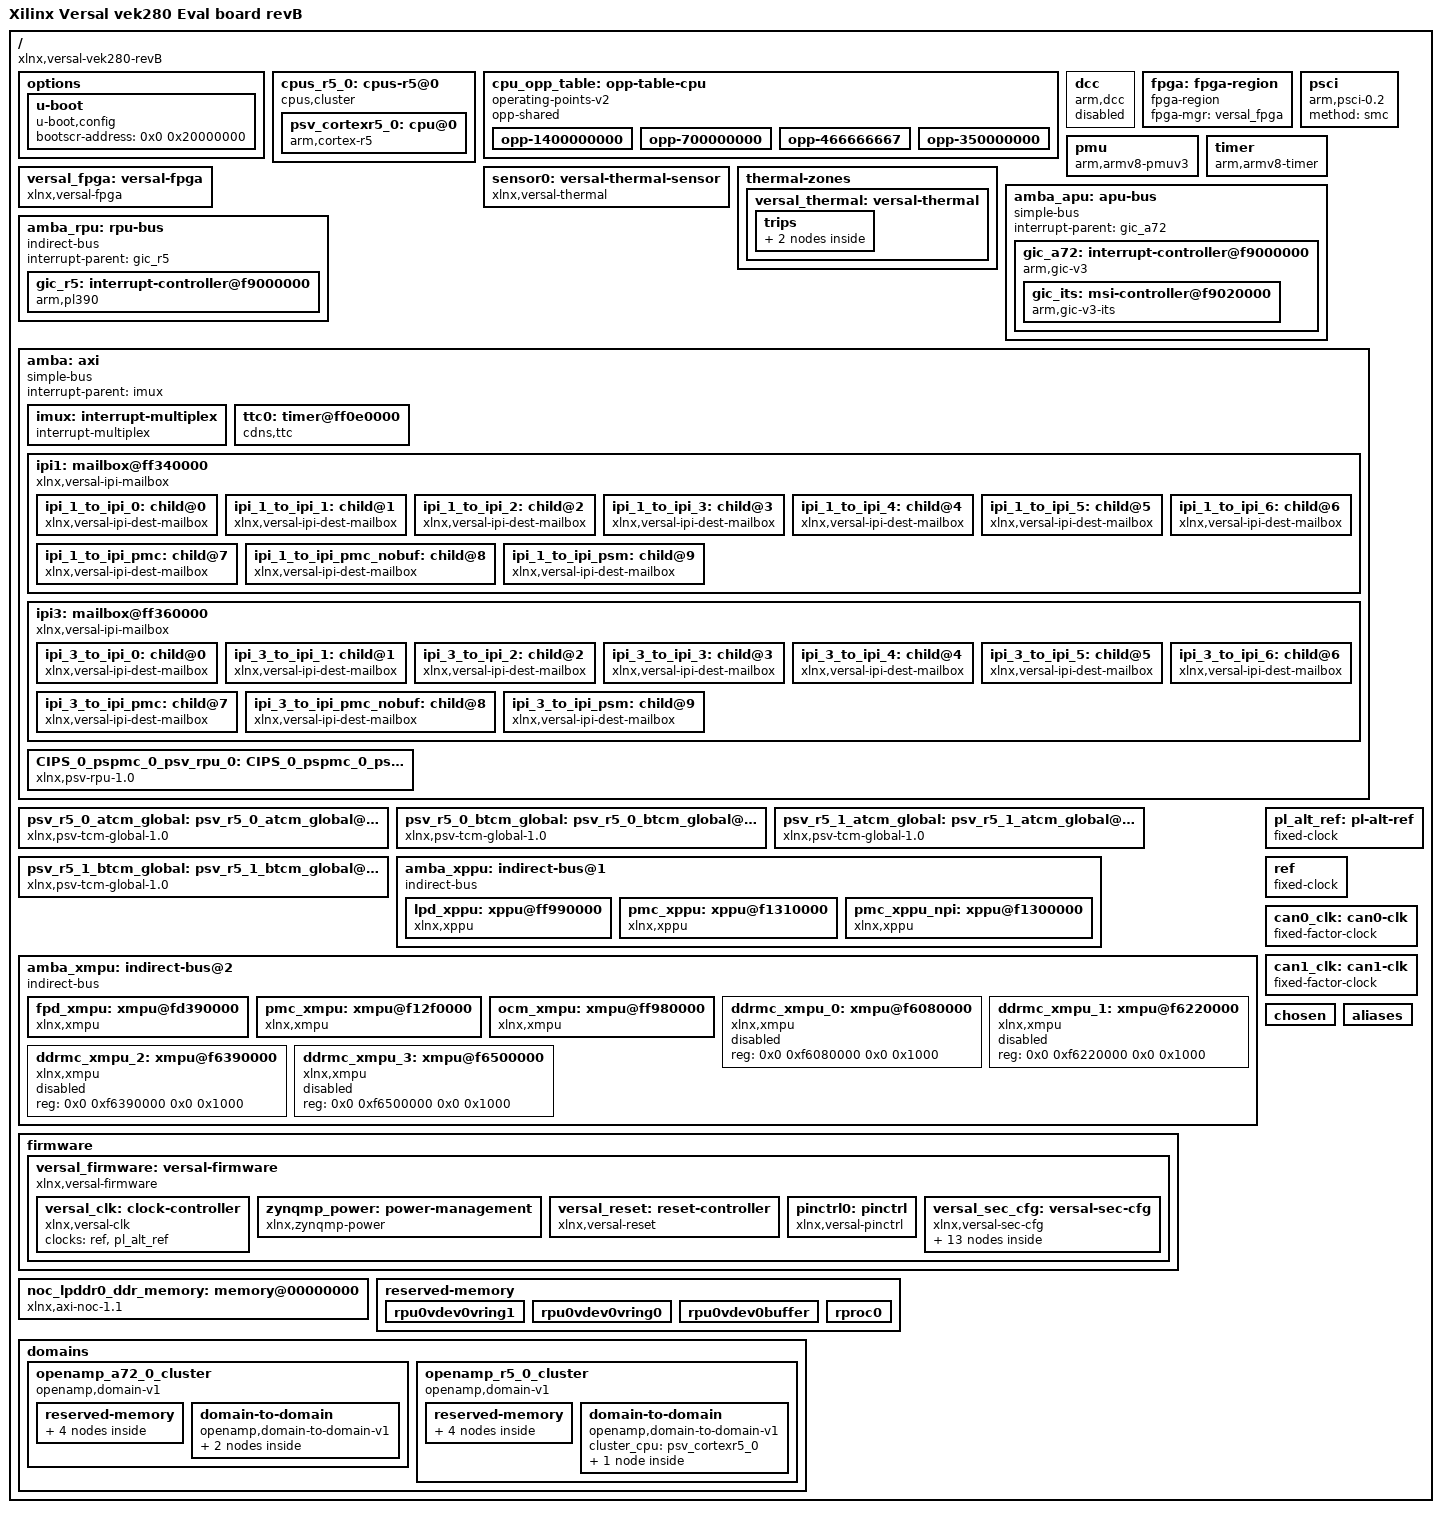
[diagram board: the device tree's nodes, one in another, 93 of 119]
/dts-v1/;
/ {
        compatible = "xlnx,versal-vek280-revB", "xlnx,versal-vek280", "xlnx,versal", "Xilinx Versal vek280 Eval board revB", "Xilinx Versal vek280 Eval board revB";
        #address-cells = <0x2>;
        #size-cells = <0x2>;
        model = "Xilinx Versal vek280 Eval board revB";
        board = "vek280";
        device_id = "xcve2802";
        slrcount = <0x1>;
        family = "Versal";
        speed_grade = "2MP";

        options {

                u-boot {
                        compatible = "u-boot,config";
                        bootscr-address = <0x0 0x20000000>;
                };
        };

        cpus_r5_0: cpus-r5@0 {
                phandle = <0xab>;
                #address-cells = <0x1>;
                #size-cells = <0x0>;
                compatible = "cpus,cluster";
                address-map = <0xf0000000 &amba 0xf0000000 0x10000000>,
                 <0xf9000000 &amba_rpu 0xf9000000 0x3000>,
                 <0x40000 &noc_lpddr0_ddr_memory 0x40000 0x7ffc0000>,
                 <0xff340000 &ipi1 0xff340000 0x10000>,
                 <0xf12f0000 &pmc_xmpu 0xf12f0000 0x10000>,
                 <0xf1300000 &pmc_xppu_npi 0xf1300000 0x10000>,
                 <0xf1310000 &pmc_xppu 0xf1310000 0x10000>,
                 <0xfd390000 &fpd_xmpu 0xfd390000 0x10000>,
                 <0xff0e0000 &ttc0 0xff0e0000 0x10000>,
                 <0xff980000 &ocm_xmpu 0xff980000 0x10000>,
                 <0xff990000 &lpd_xppu 0xff990000 0x10000>,
                 <0xff9a0000 &CIPS_0_pspmc_0_psv_rpu_0 0xff9a0000 0x10000>,
                 <0xf9000000 &gic_r5 0xf9000000 0x3000>;
                #ranges-address-cells = <0x1>;
                #ranges-size-cells = <0x1>;

                psv_cortexr5_0: cpu@0 {
                        phandle = <0xac>;
                        compatible = "arm,cortex-r5";
                        device_type = "cpu";
                        reg = <0x0>;
                        operating-points-v2 = <&cpu_opp_table>;
                        power-domains = <&versal_firmware 0x18110005>;
                        xlnx,is-cache-coherent = <0x0>;
                        xlnx,pss-ref-clk-freq = <0x1fca034>;
                        xlnx,ip-name = "psv_cortexr5";
                        access-val = <0xff>;
                        bus-handle = <0x1>;
                        xlnx,cpu-clk-freq-hz = <0x23c343db>;
                        cpu-frequency = <0x23c343db>;
                };
        };

        cpu_opp_table: opp-table-cpu {
                phandle = <0x7d>;
                compatible = "operating-points-v2";
                opp-shared;

                opp-1400000000 {
                        opp-hz = <0x0 0x53724e00>;
                        clock-latency-ns = <0x7a120>;
                        opp-microvolt = <0xf4240>;
                };

                opp-700000000 {
                        opp-hz = <0x0 0x29b92700>;
                        clock-latency-ns = <0x7a120>;
                        opp-microvolt = <0xf4240>;
                };

                opp-466666667 {
                        opp-hz = <0x0 0x1bd0c4ab>;
                        clock-latency-ns = <0x7a120>;
                        opp-microvolt = <0xf4240>;
                };

                opp-350000000 {
                        opp-hz = <0x0 0x14dc9380>;
                        clock-latency-ns = <0x7a120>;
                        opp-microvolt = <0xf4240>;
                };
        };

        dcc: dcc {
                phandle = <0xaf>;
                compatible = "arm,dcc";
                status = "disabled";
                bootph-all;
        };

        fpga: fpga-region {
                phandle = <0xb0>;
                compatible = "fpga-region";
                fpga-mgr = <&versal_fpga>;
                #address-cells = <0x2>;
                #size-cells = <0x2>;
        };

        psci: psci {
                phandle = <0xb1>;
                compatible = "arm,psci-0.2";
                method = "smc";
        };

        pmu {
                compatible = "arm,armv8-pmuv3";
                interrupt-parent = <&imux>;
                interrupts = <0x1 0x7 0x304>;
        };

        timer: timer {
                phandle = <0xb2>;
                compatible = "arm,armv8-timer";
                interrupt-parent = <&imux>;
                interrupts = <0x1 0xd 0x4 0x1 0xe 0x4 0x1 0xb 0x4 0x1 0xa 0x4>;
        };

        versal_fpga: versal-fpga {
                phandle = <0x97>;
                compatible = "xlnx,versal-fpga";
        };

        sensor0: versal-thermal-sensor {
                phandle = <0x99>;
                compatible = "xlnx,versal-thermal";
                #thermal-sensor-cells = <0x0>;
                io-channel-names = "sysmon-temp-channel";
        };

        thermal-zones {

                versal_thermal: versal-thermal {
                        phandle = <0xb3>;
                        polling-delay-passive = <0xfa>;
                        polling-delay = <0x3e8>;
                        thermal-sensors = <0x99>;

                        trips {

                                temp_alert: temp-alert {
                                        phandle = <0xb4>;
                                        temperature = <0x11170>;
                                        hysteresis = <0x0>;
                                        type = "passive";
                                };

                                ot_crit: ot-crit {
                                        phandle = <0xb5>;
                                        temperature = <0x1e848>;
                                        hysteresis = <0x0>;
                                        type = "critical";
                                };
                        };
                };
        };

        amba_apu: apu-bus {
                phandle = <0x2>;
                compatible = "simple-bus";
                #address-cells = <0x2>;
                #size-cells = <0x2>;
                ranges;
                interrupt-parent = <&gic_a72>;
                bootph-all;

                gic_a72: interrupt-controller@f9000000 {
                        phandle = <0x4d>;
                        compatible = "arm,gic-v3";
                        #interrupt-cells = <0x3>;
                        #address-cells = <0x2>;
                        #size-cells = <0x2>;
                        ranges;
                        reg = <0x0 0xf9000000 0x0 0x80000 0x0 0xf9080000 0x0 0x80000>;
                        interrupt-controller;
                        interrupt-parent = <&gic_a72>;
                        interrupts = <0x1 0x9 0x4>;
                        status = "okay";
                        xlnx,apu-gic-its-ctl = <0xf9020000>;
                        xlnx,ip-name = "psv_acpu_gic";
                        xlnx,name = "CIPS_0_pspmc_0_psv_acpu_gic";

                        gic_its: msi-controller@f9020000 {
                                phandle = <0x8>;
                                compatible = "arm,gic-v3-its";
                                status = "okay";
                                msi-controller;
                                #msi-cells = <0x1>;
                                reg = <0x0 0xf9020000 0x0 0x20000>;
                        };
                };
        };

        amba_rpu: rpu-bus {
                phandle = <0x8a>;
                compatible = "indirect-bus";
                #address-cells = <0x2>;
                #size-cells = <0x2>;
                ranges;
                interrupt-parent = <&gic_r5>;
                bootph-all;

                gic_r5: interrupt-controller@f9000000 {
                        phandle = <0x8f>;
                        compatible = "arm,pl390";
                        #interrupt-cells = <0x3>;
                        interrupt-controller;
                        status = "okay";
                        reg = <0x0 0xf9000000 0x0 0x1000 0x0 0xf9001000 0x0 0x1000>;
                        xlnx,ip-name = "psv_rcpu_gic";
                        xlnx,name = "CIPS_0_pspmc_0_psv_rcpu_gic";
                };
        };

        amba: axi {
                phandle = <0x1>;
                compatible = "simple-bus";
                #address-cells = <0x2>;
                #size-cells = <0x2>;
                ranges;
                interrupt-parent = <&imux>;
                bootph-all;

                imux: interrupt-multiplex {
                        phandle = <0x98>;
                        compatible = "interrupt-multiplex";
                        #address-cells = <0x0>;
                        #interrupt-cells = <0x3>;
                        interrupt-controller;
                        interrupt-parent = <&gic_a72>,
                         <&gic_r5>;
                        interrupt-map-mask = <0x0 0xffff 0x0>;
                        interrupt-map = <0x0 0x14 0x0 &gic_a72 0x0 0x14 0x1>,
                         <0x0 0x15 0x0 &gic_a72 0x0 0x15 0x1>,
                         <0x0 0x6a 0x0 &gic_a72 0x0 0x6a 0x4>,
                         <0x0 0x3c 0x0 &gic_a72 0x0 0x3c 0x4>,
                         <0x0 0x3d 0x0 &gic_a72 0x0 0x3d 0x4>,
                         <0x0 0x3e 0x0 &gic_a72 0x0 0x3e 0x4>,
                         <0x0 0x3f 0x0 &gic_a72 0x0 0x3f 0x4>,
                         <0x0 0x40 0x0 &gic_a72 0x0 0x40 0x4>,
                         <0x0 0x41 0x0 &gic_a72 0x0 0x41 0x4>,
                         <0x0 0x42 0x0 &gic_a72 0x0 0x42 0x4>,
                         <0x0 0x43 0x0 &gic_a72 0x0 0x43 0x4>,
                         <0x0 0x38 0x0 &gic_a72 0x0 0x38 0x4>,
                         <0x0 0x3a 0x0 &gic_a72 0x0 0x3a 0x4>,
                         <0x0 0xd 0x0 &gic_a72 0x0 0xd 0x4>,
                         <0x0 0x7a 0x0 &gic_a72 0x0 0x7a 0x4>,
                         <0x0 0xe 0x0 &gic_a72 0x0 0xe 0x4>,
                         <0x0 0xf 0x0 &gic_a72 0x0 0xf 0x4>,
                         <0x0 0x8e 0x0 &gic_a72 0x0 0x8e 0x4>,
                         <0x0 0x8f 0x0 &gic_a72 0x0 0x8f 0x4>,
                         <0x0 0x7e 0x0 &gic_a72 0x0 0x7e 0x4>,
                         <0x0 0x80 0x0 &gic_a72 0x0 0x80 0x4>,
                         <0x0 0x12 0x0 &gic_a72 0x0 0x12 0x4>,
                         <0x0 0x13 0x0 &gic_a72 0x0 0x13 0x4>,
                         <0x0 0x6b 0x0 &gic_a72 0x0 0x6b 0x4>,
                         <0x0 0x7c 0x0 &gic_a72 0x0 0x7c 0x4>,
                         <0x0 0x7d 0x0 &gic_a72 0x0 0x7d 0x4>,
                         <0x0 0x10 0x0 &gic_a72 0x0 0x10 0x4>,
                         <0x0 0x11 0x0 &gic_a72 0x0 0x11 0x4>,
                         <0x0 0x16 0x0 &gic_a72 0x0 0x16 0x4>,
                         <0x0 0x1a 0x0 &gic_a72 0x0 0x1a 0x4>,
                         <0x0 0x4a 0x0 &gic_a72 0x0 0x4a 0x4>,
                         <0x0 0x48 0x0 &gic_a72 0x0 0x48 0x4>,
                         <0x0 0x1e 0x0 &gic_a72 0x0 0x1e 0x4>,
                         <0x0 0x1f 0x0 &gic_a72 0x0 0x1f 0x4>,
                         <0x0 0x83 0x0 &gic_a72 0x0 0x83 0x4>,
                         <0x0 0x84 0x0 &gic_a72 0x0 0x84 0x4>,
                         <0x0 0x14 0x0 &gic_r5 0x0 0x14 0x1>,
                         <0x0 0x15 0x0 &gic_r5 0x0 0x15 0x1>,
                         <0x0 0x6a 0x0 &gic_r5 0x0 0x6a 0x4>,
                         <0x0 0x3c 0x0 &gic_r5 0x0 0x3c 0x4>,
                         <0x0 0x3d 0x0 &gic_r5 0x0 0x3d 0x4>,
                         <0x0 0x3e 0x0 &gic_r5 0x0 0x3e 0x4>,
                         <0x0 0x3f 0x0 &gic_r5 0x0 0x3f 0x4>,
                         <0x0 0x40 0x0 &gic_r5 0x0 0x40 0x4>,
                         <0x0 0x41 0x0 &gic_r5 0x0 0x41 0x4>,
                         <0x0 0x42 0x0 &gic_r5 0x0 0x42 0x4>,
                         <0x0 0x43 0x0 &gic_r5 0x0 0x43 0x4>,
                         <0x0 0x38 0x0 &gic_r5 0x0 0x38 0x4>,
                         <0x0 0x3a 0x0 &gic_r5 0x0 0x3a 0x4>,
                         <0x0 0xd 0x0 &gic_r5 0x0 0xd 0x4>,
                         <0x0 0x7a 0x0 &gic_r5 0x0 0x7a 0x4>,
                         <0x0 0xe 0x0 &gic_r5 0x0 0xe 0x4>,
                         <0x0 0xf 0x0 &gic_r5 0x0 0xf 0x4>,
                         <0x0 0x8e 0x0 &gic_r5 0x0 0x8e 0x4>,
                         <0x0 0x8f 0x0 &gic_r5 0x0 0x8f 0x4>,
                         <0x0 0x7e 0x0 &gic_r5 0x0 0x7e 0x4>,
                         <0x0 0x80 0x0 &gic_r5 0x0 0x80 0x4>,
                         <0x0 0x12 0x0 &gic_r5 0x0 0x12 0x4>,
                         <0x0 0x13 0x0 &gic_r5 0x0 0x13 0x4>,
                         <0x0 0x6b 0x0 &gic_r5 0x0 0x6b 0x4>,
                         <0x0 0x7c 0x0 &gic_r5 0x0 0x7c 0x4>,
                         <0x0 0x7d 0x0 &gic_r5 0x0 0x7d 0x4>,
                         <0x0 0x10 0x0 &gic_r5 0x0 0x10 0x4>,
                         <0x0 0x11 0x0 &gic_r5 0x0 0x11 0x4>,
                         <0x0 0x16 0x0 &gic_r5 0x0 0x16 0x4>,
                         <0x0 0x1a 0x0 &gic_r5 0x0 0x1a 0x4>,
                         <0x0 0x4a 0x0 &gic_r5 0x0 0x4a 0x4>,
                         <0x0 0x48 0x0 &gic_r5 0x0 0x48 0x4>,
                         <0x0 0x1e 0x0 &gic_r5 0x0 0x1e 0x4>,
                         <0x0 0x1f 0x0 &gic_r5 0x0 0x1f 0x4>,
                         <0x0 0x83 0x0 &gic_r5 0x0 0x83 0x4>,
                         <0x0 0x84 0x0 &gic_r5 0x0 0x84 0x4>;
                };

                ttc0: timer@ff0e0000 {
                        phandle = <0x64>;
                        compatible = "cdns,ttc";
                        status = "okay";
                        interrupts = <0x0 0x25 0x4 0x0 0x26 0x4 0x0 0x27 0x4>;
                        interrupt-parent = <&imux>;
                        reg = <0x0 0xff0e0000 0x0 0x1000>;
                        timer-width = <0x20>;
                        clocks = <&versal_clk 0x27>;
                        power-domains = <&versal_firmware 0x18224024>;
                        xlnx,ttc-board-interface = "custom";
                        xlnx,ttc-clk2-freq-hz = <0x8f0d0f7>;
                        xlnx,ttc-clk1-clksrc = <0x0>;
                        xlnx,clock-freq = <0x8f0d0f7>;
                        xlnx,ttc-clk2-clksrc = <0x0>;
                        xlnx,ip-name = "psv_ttc";
                        xlnx,ttc-clk0-freq-hz = <0x8f0d0f7>;
                        xlnx,ttc-clk1-freq-hz = <0x8f0d0f7>;
                        xlnx,ttc-clk0-clksrc = <0x0>;
                        xlnx,name = "CIPS_0_pspmc_0_psv_ttc_0";
                };

                ipi1: mailbox@ff340000 {
                        status = "okay";
                        compatible = "xlnx,versal-ipi-mailbox";
                        interrupt-parent = <&imux>;
                        interrupts = <0x0 0x1f 0x4>;
                        reg = <0x0 0xff340000 0x0 0x10000 0x0 0xff3f0600 0x0 0x200>;
                        xlnx,ipi-bitmask = <0x8>;
                        xlnx,ipi-id = <0x3>;
                        xlnx,ipi-buf-index = <0x3>;
                        #address-cells = <0x2>;
                        #size-cells = <0x2>;
                        ranges;
                        xlnx,cpu-name = "R5_0";
                        xlnx,buffer-base = <0xff3f0600>;
                        xlnx,buffer-index = <0x3>;
                        xlnx,ip-name = "psv_ipi";
                        xlnx,ipi-target-count = <0xa>;
                        reg-names = "ctrl", "msg";
                        xlnx,int-id = <0x3f>;
                        xlnx,bit-position = <0x3>;
                        xlnx,name = "CIPS_0_pspmc_0_psv_ipi_1";
                        phandle = <0x8b>;

                        ipi_1_to_ipi_0: child@0 {
                                phandle = <0xfa>;
                                compatible = "xlnx,versal-ipi-dest-mailbox";
                                xlnx,ipi-bitmask = <0x4>;
                                xlnx,cpu-name = "A72";
                                xlnx,ipi-rsp-msg-buf = <0xff3f06a0>;
                                #mbox-cells = <0x1>;
                                xlnx,ipi-id = <0x2>;
                                reg = <0x0 0xff330000 0x0 0x10000 0x0 0xff3f0400 0x0 0x200>;
                                xlnx,ipi-buf-index = <0x2>;
                                xlnx,ipi-req-msg-buf = <0xff3f0680>;
                                reg-names = "ctrl", "msg";
                        };

                        ipi_1_to_ipi_1: child@1 {
                                phandle = <0xfb>;
                                compatible = "xlnx,versal-ipi-dest-mailbox";
                                xlnx,ipi-bitmask = <0x8>;
                                xlnx,cpu-name = "R5_0";
                                xlnx,ipi-rsp-msg-buf = <0xff3f06e0>;
                                #mbox-cells = <0x1>;
                                xlnx,ipi-id = <0x3>;
                                reg = <0x0 0xff340000 0x0 0x10000 0x0 0xff3f0600 0x0 0x200>;
                                xlnx,ipi-buf-index = <0x3>;
                                xlnx,ipi-req-msg-buf = <0xff3f06c0>;
                                reg-names = "ctrl", "msg";
                        };

                        ipi_1_to_ipi_2: child@2 {
                                phandle = <0xfc>;
                                compatible = "xlnx,versal-ipi-dest-mailbox";
                                xlnx,ipi-bitmask = <0x10>;
                                xlnx,cpu-name = "R5_1";
                                xlnx,ipi-rsp-msg-buf = <0xff3f0720>;
                                #mbox-cells = <0x1>;
                                xlnx,ipi-id = <0x4>;
                                reg = <0x0 0xff350000 0x0 0x10000 0x0 0xff3f0800 0x0 0x200>;
                                xlnx,ipi-buf-index = <0x4>;
                                xlnx,ipi-req-msg-buf = <0xff3f0700>;
                                reg-names = "ctrl", "msg";
                        };

                        ipi_1_to_ipi_3: child@3 {
                                phandle = <0xfd>;
                                compatible = "xlnx,versal-ipi-dest-mailbox";
                                xlnx,ipi-bitmask = <0x20>;
                                xlnx,cpu-name = "A72";
                                xlnx,ipi-rsp-msg-buf = <0xff3f0760>;
                                #mbox-cells = <0x1>;
                                xlnx,ipi-id = <0x5>;
                                reg = <0x0 0xff360000 0x0 0x10000 0x0 0xff3f0a00 0x0 0x200>;
                                xlnx,ipi-buf-index = <0x5>;
                                xlnx,ipi-req-msg-buf = <0xff3f0740>;
                                reg-names = "ctrl", "msg";
                        };

                        ipi_1_to_ipi_4: child@4 {
                                phandle = <0xfe>;
                                compatible = "xlnx,versal-ipi-dest-mailbox";
                                xlnx,ipi-bitmask = <0x40>;
                                xlnx,cpu-name = "A72";
                                xlnx,ipi-rsp-msg-buf = <0xff3f07a0>;
                                #mbox-cells = <0x1>;
                                xlnx,ipi-id = <0x6>;
                                reg = <0x0 0xff370000 0x0 0x10000 0x0 0xff3f0c00 0x0 0x200>;
                                xlnx,ipi-buf-index = <0x6>;
                                xlnx,ipi-req-msg-buf = <0xff3f0780>;
                                reg-names = "ctrl", "msg";
                        };

                        ipi_1_to_ipi_5: child@5 {
                                phandle = <0xff>;
                                compatible = "xlnx,versal-ipi-dest-mailbox";
                                xlnx,ipi-bitmask = <0x80>;
                                xlnx,cpu-name = "A72";
                                xlnx,ipi-rsp-msg-buf = <0xff3f07e0>;
                                #mbox-cells = <0x1>;
                                xlnx,ipi-id = <0x7>;
                                reg = <0x0 0xff380000 0x0 0x10000 0x0 0xff3f0e00 0x0 0x200>;
                                xlnx,ipi-buf-index = <0x7>;
                                xlnx,ipi-req-msg-buf = <0xff3f07c0>;
                                reg-names = "ctrl", "msg";
                        };

                        ipi_1_to_ipi_6: child@6 {
                                phandle = <0x100>;
                                compatible = "xlnx,versal-ipi-dest-mailbox";
                                xlnx,ipi-bitmask = <0x200>;
                                xlnx,cpu-name = "A72";
                                #mbox-cells = <0x1>;
                                xlnx,ipi-id = <0x9>;
                                reg = <0x0 0xff3a0000 0x0 0x10000>;
                                xlnx,ipi-buf-index = <0xffff>;
                                reg-names = "ctrl";
                        };

                        ipi_1_to_ipi_pmc: child@7 {
                                phandle = <0x101>;
                                compatible = "xlnx,versal-ipi-dest-mailbox";
                                xlnx,ipi-bitmask = <0x2>;
                                xlnx,cpu-name = "PMC";
                                xlnx,ipi-rsp-msg-buf = <0xff3f0660>;
                                #mbox-cells = <0x1>;
                                xlnx,ipi-id = <0x1>;
                                reg = <0x0 0xff320000 0x0 0x10000 0x0 0xff3f0200 0x0 0x200>;
                                xlnx,ipi-buf-index = <0x1>;
                                xlnx,ipi-req-msg-buf = <0xff3f0640>;
                                reg-names = "ctrl", "msg";
                        };

                        ipi_1_to_ipi_pmc_nobuf: child@8 {
                                phandle = <0x102>;
                                compatible = "xlnx,versal-ipi-dest-mailbox";
                                xlnx,ipi-bitmask = <0x100>;
                                xlnx,cpu-name = "PMC";
                                #mbox-cells = <0x1>;
                                xlnx,ipi-id = <0x8>;
                                reg = <0x0 0xff390000 0x0 0x10000>;
                                xlnx,ipi-buf-index = <0xffff>;
                                reg-names = "ctrl";
                        };

                        ipi_1_to_ipi_psm: child@9 {
                                phandle = <0x103>;
                                compatible = "xlnx,versal-ipi-dest-mailbox";
                                xlnx,ipi-bitmask = <0x1>;
                                xlnx,cpu-name = "PSM";
                                xlnx,ipi-rsp-msg-buf = <0xff3f0620>;
                                #mbox-cells = <0x1>;
                                xlnx,ipi-id = <0x0>;
                                reg = <0x0 0xff310000 0x0 0x10000 0x0 0xff3f0000 0x0 0x200>;
                                xlnx,ipi-buf-index = <0x0>;
                                xlnx,ipi-req-msg-buf = <0xff3f0600>;
                                reg-names = "ctrl", "msg";
                        };
                };

                ipi3: mailbox@ff360000 {
                        status = "okay";
                        compatible = "xlnx,versal-ipi-mailbox";
                        interrupt-parent = <&imux>;
                        interrupts = <0x0 0x21 0x4>;
                        reg = <0x0 0xff360000 0x0 0x10000 0x0 0xff3f0a00 0x0 0x200>;
                        xlnx,ipi-bitmask = <0x20>;
                        xlnx,ipi-id = <0x5>;
                        xlnx,ipi-buf-index = <0x5>;
                        #address-cells = <0x2>;
                        #size-cells = <0x2>;
                        ranges;
                        xlnx,cpu-name = "A72";
                        xlnx,buffer-base = <0xff3f0a00>;
                        xlnx,buffer-index = <0x5>;
                        xlnx,ip-name = "psv_ipi";
                        xlnx,ipi-target-count = <0xa>;
                        reg-names = "ctrl", "msg";
                        xlnx,int-id = <0x41>;
                        xlnx,bit-position = <0x5>;
                        xlnx,name = "CIPS_0_pspmc_0_psv_ipi_3";
                        phandle = <0xa>;

                        ipi_3_to_ipi_0: child@0 {
                                phandle = <0x10e>;
                                compatible = "xlnx,versal-ipi-dest-mailbox";
                                xlnx,ipi-bitmask = <0x4>;
                                xlnx,cpu-name = "A72";
                                xlnx,ipi-rsp-msg-buf = <0xff3f0aa0>;
                                #mbox-cells = <0x1>;
                                xlnx,ipi-id = <0x2>;
                                reg = <0x0 0xff330000 0x0 0x10000 0x0 0xff3f0400 0x0 0x200>;
                                xlnx,ipi-buf-index = <0x2>;
                                xlnx,ipi-req-msg-buf = <0xff3f0a80>;
                                reg-names = "ctrl", "msg";
                        };

                        ipi_3_to_ipi_1: child@1 {
                                phandle = <0x10f>;
                                compatible = "xlnx,versal-ipi-dest-mailbox";
                                xlnx,ipi-bitmask = <0x8>;
                                xlnx,cpu-name = "R5_0";
                                xlnx,ipi-rsp-msg-buf = <0xff3f0ae0>;
                                #mbox-cells = <0x1>;
                                xlnx,ipi-id = <0x3>;
                                reg = <0x0 0xff340000 0x0 0x10000 0x0 0xff3f0600 0x0 0x200>;
                                xlnx,ipi-buf-index = <0x3>;
                                xlnx,ipi-req-msg-buf = <0xff3f0ac0>;
                                reg-names = "ctrl", "msg";
                        };

                        ipi_3_to_ipi_2: child@2 {
                                phandle = <0x110>;
                                compatible = "xlnx,versal-ipi-dest-mailbox";
                                xlnx,ipi-bitmask = <0x10>;
                                xlnx,cpu-name = "R5_1";
                                xlnx,ipi-rsp-msg-buf = <0xff3f0b20>;
                                #mbox-cells = <0x1>;
                                xlnx,ipi-id = <0x4>;
                                reg = <0x0 0xff350000 0x0 0x10000 0x0 0xff3f0800 0x0 0x200>;
                                xlnx,ipi-buf-index = <0x4>;
                                xlnx,ipi-req-msg-buf = <0xff3f0b00>;
                                reg-names = "ctrl", "msg";
                        };

                        ipi_3_to_ipi_3: child@3 {
                                phandle = <0x111>;
                                compatible = "xlnx,versal-ipi-dest-mailbox";
                                xlnx,ipi-bitmask = <0x20>;
                                xlnx,cpu-name = "A72";
                                xlnx,ipi-rsp-msg-buf = <0xff3f0b60>;
                                #mbox-cells = <0x1>;
                                xlnx,ipi-id = <0x5>;
                                reg = <0x0 0xff360000 0x0 0x10000 0x0 0xff3f0a00 0x0 0x200>;
                                xlnx,ipi-buf-index = <0x5>;
                                xlnx,ipi-req-msg-buf = <0xff3f0b40>;
                                reg-names = "ctrl", "msg";
                        };

                        ipi_3_to_ipi_4: child@4 {
                                phandle = <0x112>;
                                compatible = "xlnx,versal-ipi-dest-mailbox";
                                xlnx,ipi-bitmask = <0x40>;
                                xlnx,cpu-name = "A72";
                                xlnx,ipi-rsp-msg-buf = <0xff3f0ba0>;
                                #mbox-cells = <0x1>;
                                xlnx,ipi-id = <0x6>;
                                reg = <0x0 0xff370000 0x0 0x10000 0x0 0xff3f0c00 0x0 0x200>;
                                xlnx,ipi-buf-index = <0x6>;
                                xlnx,ipi-req-msg-buf = <0xff3f0b80>;
                                reg-names = "ctrl", "msg";
                        };

                        ipi_3_to_ipi_5: child@5 {
                                phandle = <0x113>;
                                compatible = "xlnx,versal-ipi-dest-mailbox";
                                xlnx,ipi-bitmask = <0x80>;
                                xlnx,cpu-name = "A72";
                                xlnx,ipi-rsp-msg-buf = <0xff3f0be0>;
                                #mbox-cells = <0x1>;
                                xlnx,ipi-id = <0x7>;
                                reg = <0x0 0xff380000 0x0 0x10000 0x0 0xff3f0e00 0x0 0x200>;
                                xlnx,ipi-buf-index = <0x7>;
                                xlnx,ipi-req-msg-buf = <0xff3f0bc0>;
                                reg-names = "ctrl", "msg";
                        };

                        ipi_3_to_ipi_6: child@6 {
                                phandle = <0x114>;
                                compatible = "xlnx,versal-ipi-dest-mailbox";
                                xlnx,ipi-bitmask = <0x200>;
                                xlnx,cpu-name = "A72";
                                #mbox-cells = <0x1>;
                                xlnx,ipi-id = <0x9>;
                                reg = <0x0 0xff3a0000 0x0 0x10000>;
                                xlnx,ipi-buf-index = <0xffff>;
                                reg-names = "ctrl";
                        };

                        ipi_3_to_ipi_pmc: child@7 {
                                phandle = <0x115>;
                                compatible = "xlnx,versal-ipi-dest-mailbox";
                                xlnx,ipi-bitmask = <0x2>;
                                xlnx,cpu-name = "PMC";
                                xlnx,ipi-rsp-msg-buf = <0xff3f0a60>;
                                #mbox-cells = <0x1>;
                                xlnx,ipi-id = <0x1>;
                                reg = <0x0 0xff320000 0x0 0x10000 0x0 0xff3f0200 0x0 0x200>;
                                xlnx,ipi-buf-index = <0x1>;
                                xlnx,ipi-req-msg-buf = <0xff3f0a40>;
                                reg-names = "ctrl", "msg";
                        };

                        ipi_3_to_ipi_pmc_nobuf: child@8 {
                                phandle = <0x116>;
                                compatible = "xlnx,versal-ipi-dest-mailbox";
                                xlnx,ipi-bitmask = <0x100>;
                                xlnx,cpu-name = "PMC";
                                #mbox-cells = <0x1>;
                                xlnx,ipi-id = <0x8>;
                                reg = <0x0 0xff390000 0x0 0x10000>;
                                xlnx,ipi-buf-index = <0xffff>;
                                reg-names = "ctrl";
                        };

                        ipi_3_to_ipi_psm: child@9 {
                                phandle = <0x117>;
                                compatible = "xlnx,versal-ipi-dest-mailbox";
                                xlnx,ipi-bitmask = <0x1>;
                                xlnx,cpu-name = "PSM";
                                xlnx,ipi-rsp-msg-buf = <0xff3f0a20>;
                                #mbox-cells = <0x1>;
                                xlnx,ipi-id = <0x0>;
                                reg = <0x0 0xff310000 0x0 0x10000 0x0 0xff3f0000 0x0 0x200>;
                                xlnx,ipi-buf-index = <0x0>;
                                xlnx,ipi-req-msg-buf = <0xff3f0a00>;
                                reg-names = "ctrl", "msg";
                        };
                };

                CIPS_0_pspmc_0_psv_rpu_0: CIPS_0_pspmc_0_psv_rpu_0@ff9a0000 {
                        phandle = <0x6d>;
                        compatible = "xlnx,psv-rpu-1.0";
                        status = "okay";
                        xlnx,ip-name = "psv_rpu";
                        reg = <0x0 0xff9a0000 0x0 0x10000>;
                        xlnx,name = "CIPS_0_pspmc_0_psv_rpu_0";
                };
        };

        psv_r5_0_atcm_global: psv_r5_0_atcm_global@ffe00000 {
                compatible = "xlnx,psv-tcm-global-1.0", "mmio-sram";
                power-domains = <&versal_firmware 0x1831800b>;
                reg = <0x0 0xffe00000 0x0 0x10000>;
                status = "okay";
                xlnx,ip-name = "psv_tcm_global";
                xlnx,is-hierarchy;
                xlnx,name = "CIPS_0_pspmc_0_psv_r5_0_atcm_global";
                phandle = <0x79>;
        };

        psv_r5_0_btcm_global: psv_r5_0_btcm_global@ffe20000 {
                compatible = "xlnx,psv-tcm-global-1.0", "mmio-sram";
                power-domains = <&versal_firmware 0x1831800c>;
                reg = <0x0 0xffe20000 0x0 0x10000>;
                status = "okay";
                xlnx,ip-name = "psv_tcm_global";
                xlnx,is-hierarchy;
                xlnx,name = "CIPS_0_pspmc_0_psv_r5_0_btcm_global";
                phandle = <0x141>;
        };

        psv_r5_1_atcm_global: psv_r5_1_atcm_global@ffe90000 {
                phandle = <0x7a>;
                compatible = "xlnx,psv-tcm-global-1.0", "mmio-sram";
                power-domains = <&versal_firmware 0x1831800d>;
                reg = <0x0 0xffe90000 0x0 0x10000>;
                status = "okay";
                xlnx,ip-name = "psv_tcm_global";
                xlnx,name = "CIPS_0_pspmc_0_psv_r5_1_atcm_global";
        };

        psv_r5_1_btcm_global: psv_r5_1_btcm_global@ffeb0000 {
                phandle = <0x7b>;
                compatible = "xlnx,psv-tcm-global-1.0", "mmio-sram";
                power-domains = <&versal_firmware 0x1831800e>;
                reg = <0x0 0xffeb0000 0x0 0x10000>;
                status = "okay";
                xlnx,ip-name = "psv_tcm_global";
                xlnx,name = "CIPS_0_pspmc_0_psv_r5_1_btcm_global";
        };

        amba_xppu: indirect-bus@1 {
                phandle = <0x142>;
                compatible = "indirect-bus";
                #address-cells = <0x2>;
                #size-cells = <0x2>;

                lpd_xppu: xppu@ff990000 {
                        phandle = <0x6c>;
                        compatible = "xlnx,xppu";
                        #firewall-cells = <0x0>;
                        reg = <0x0 0xff990000 0x0 0x2000>;
                        status = "okay";
                        xlnx,ip-name = "psv_lpd_xppu";
                        xlnx,name = "CIPS_0_pspmc_0_psv_lpd_xppu_0";
                };

                pmc_xppu: xppu@f1310000 {
                        phandle = <0x4a>;
                        compatible = "xlnx,xppu";
                        #firewall-cells = <0x0>;
                        reg = <0x0 0xf1310000 0x0 0x2000>;
                        status = "okay";
                        xlnx,ip-name = "psv_pmc_xppu";
                        xlnx,name = "CIPS_0_pspmc_0_psv_pmc_xppu_0";
                };

                pmc_xppu_npi: xppu@f1300000 {
                        phandle = <0x49>;
                        compatible = "xlnx,xppu";
                        #firewall-cells = <0x0>;
                        reg = <0x0 0xf1300000 0x0 0x2000>;
                        status = "okay";
                        xlnx,ip-name = "psv_pmc_xppu_npi";
                        xlnx,name = "CIPS_0_pspmc_0_psv_pmc_xppu_npi_0";
                };
        };

        amba_xmpu: indirect-bus@2 {
                phandle = <0x143>;
                compatible = "indirect-bus";
                #address-cells = <0x2>;
                #size-cells = <0x2>;

                fpd_xmpu: xmpu@fd390000 {
                        phandle = <0x53>;
                        compatible = "xlnx,xmpu";
                        #firewall-cells = <0x0>;
                        reg = <0x0 0xfd390000 0x0 0x1000>;
                        status = "okay";
                        xlnx,ip-name = "psv_fpd_slave_xmpu";
                        xlnx,name = "CIPS_0_pspmc_0_psv_fpd_slave_xmpu_0";
                };

                pmc_xmpu: xmpu@f12f0000 {
                        phandle = <0x48>;
                        compatible = "xlnx,xmpu";
                        #firewall-cells = <0x0>;
                        reg = <0x0 0xf12f0000 0x0 0x1000>;
                        status = "okay";
                        xlnx,ip-name = "psv_pmc_xmpu";
                        xlnx,name = "CIPS_0_pspmc_0_psv_pmc_xmpu_0";
                };

                ocm_xmpu: xmpu@ff980000 {
                        phandle = <0x6b>;
                        compatible = "xlnx,xmpu";
                        #firewall-cells = <0x0>;
                        reg = <0x0 0xff980000 0x0 0x1000>;
                        status = "okay";
                        xlnx,ip-name = "psv_ocm_xmpu";
                        xlnx,name = "CIPS_0_pspmc_0_psv_ocm_xmpu_0";
                };

                ddrmc_xmpu_0: xmpu@f6080000 {
                        phandle = <0x144>;
                        compatible = "xlnx,xmpu";
                        #firewall-cells = <0x0>;
                        reg = <0x0 0xf6080000 0x0 0x1000>;
                        status = "disabled";
                };

                ddrmc_xmpu_1: xmpu@f6220000 {
                        phandle = <0x145>;
                        compatible = "xlnx,xmpu";
                        #firewall-cells = <0x0>;
                        reg = <0x0 0xf6220000 0x0 0x1000>;
                        status = "disabled";
                };

                ddrmc_xmpu_2: xmpu@f6390000 {
                        phandle = <0x146>;
                        compatible = "xlnx,xmpu";
                        #firewall-cells = <0x0>;
                        reg = <0x0 0xf6390000 0x0 0x1000>;
                        status = "disabled";
                };

                ddrmc_xmpu_3: xmpu@f6500000 {
                        phandle = <0x147>;
                        compatible = "xlnx,xmpu";
                        #firewall-cells = <0x0>;
                        reg = <0x0 0xf6500000 0x0 0x1000>;
                        status = "disabled";
                };
        };

        pl_alt_ref: pl-alt-ref {
                phandle = <0xa1>;
                bootph-all;
                compatible = "fixed-clock";
                #clock-cells = <0x0>;
                clock-frequency = <0x1fca055>;
                clock-output-names = "pl_alt_ref_clk";
        };

        ref: ref {
                phandle = <0xa0>;
                bootph-all;
                compatible = "fixed-clock";
                #clock-cells = <0x0>;
                clock-frequency = <0x1fca034>;
                clock-output-names = "ref_clk";
        };

        can0_clk: can0-clk {
                phandle = <0x9a>;
                #clock-cells = <0x0>;
                compatible = "fixed-factor-clock";
                clocks = <&versal_clk 0x60>;
                clock-div = <0x2>;
                clock-mult = <0x1>;
                clock-output-names = "can0_clk";
        };

        can1_clk: can1-clk {
                phandle = <0x9b>;
                #clock-cells = <0x0>;
                compatible = "fixed-factor-clock";
                clocks = <&versal_clk 0x61>;
                clock-div = <0x2>;
                clock-mult = <0x1>;
                clock-output-names = "can1_clk";
        };

        firmware {

                versal_firmware: versal-firmware {
                        phandle = <0x7f>;
                        compatible = "xlnx,versal-firmware";
                        interrupt-parent = <&imux>;
                        bootph-all;
                        method = "smc";
                        #power-domain-cells = <0x1>;

                        versal_clk: clock-controller {
                                phandle = <0x80>;
                                bootph-all;
                                #clock-cells = <0x1>;
                                compatible = "xlnx,versal-clk";
                                clocks = <&ref>,
                                 <&pl_alt_ref>;
                                clock-names = "ref", "pl_alt_ref";
                        };

                        zynqmp_power: power-management {
                                phandle = <0x148>;
                                compatible = "xlnx,zynqmp-power";
                        };

                        versal_reset: reset-controller {
                                phandle = <0x9d>;
                                compatible = "xlnx,versal-reset";
                                #reset-cells = <0x1>;
                        };

                        pinctrl0: pinctrl {
                                phandle = <0x149>;
                                compatible = "xlnx,versal-pinctrl";
                        };

                        versal_sec_cfg: versal-sec-cfg {
                                phandle = <0x14a>;
                                compatible = "xlnx,versal-sec-cfg";

                                nvmem-layout {
                                        compatible = "fixed-layout";
                                        #address-cells = <0x1>;
                                        #size-cells = <0x1>;

                                        bbram_zeroize: bbram-zeroize@4 {
                                                phandle = <0x14b>;
                                                reg = <0x4 0x4>;
                                        };

                                        bbram_key: bbram-key@10 {
                                                phandle = <0x14c>;
                                                reg = <0x10 0x20>;
                                        };

                                        bbram_usr: bbram-usr@30 {
                                                phandle = <0x14d>;
                                                reg = <0x30 0x4>;
                                        };

                                        bbram_lock: bbram-lock@48 {
                                                phandle = <0x14e>;
                                                reg = <0x48 0x4>;
                                        };

                                        user_key0: user-key@110 {
                                                phandle = <0x14f>;
                                                reg = <0x110 0x20>;
                                        };

                                        user_key1: user-key@130 {
                                                phandle = <0x150>;
                                                reg = <0x130 0x20>;
                                        };

                                        user_key2: user-key@150 {
                                                phandle = <0x151>;
                                                reg = <0x150 0x20>;
                                        };

                                        user_key3: user-key@170 {
                                                phandle = <0x152>;
                                                reg = <0x170 0x20>;
                                        };

                                        user_key4: user-key@190 {
                                                phandle = <0x153>;
                                                reg = <0x190 0x20>;
                                        };

                                        user_key5: user-key@1b0 {
                                                phandle = <0x154>;
                                                reg = <0x1b0 0x20>;
                                        };

                                        user_key6: user-key@1d0 {
                                                phandle = <0x155>;
                                                reg = <0x1d0 0x20>;
                                        };

                                        user_key7: user-key@1f0 {
                                                phandle = <0x156>;
                                                reg = <0x1f0 0x20>;
                                        };
                                };
                        };
                };
        };

        noc_lpddr0_ddr_memory: memory@00000000 {
                phandle = <0x5>;
                compatible = "xlnx,axi-noc-1.1";
                xlnx,ip-name = "axi_noc";
                device_type = "memory";
                reg = <0x0 0x0 0x0 0x80000000 0x8 0x0 0x0 0x80000000>;
                memory_type = "memory";
        };

        chosen {
                stdout-path = "serial0:115200";
                bootargs = "console=ttyAMA0 earlycon=pl011,mmio32,0xFF000000,115200n8";
        };

        aliases {
                serial0 = "/axi/serial@ff000000";
                serial1 = "/axi/coresight@f0800000";
                i2c0 = "/axi/i2c@ff020000";
                i2c1 = "/axi/i2c@ff030000";
                ethernet0 = "/axi/ethernet@ff0c0000";
                serial2 = "/dcc";
                mmc0 = "/axi/mmc@f1050000";
                spi0 = "/axi/spi@f1010000";
                usb0 = "/axi/usb@ff9d0000";
                rtc0 = "/axi/rtc@f12a0000";
                nvmem0 = "/axi/i2c@ff030000/eeprom@54";
        };

        __symbols__ {
                cpus_a72 = "/cpus-a72@0";
                psv_cortexa72_0 = "/cpus-a72@0/cpu@0";
                psv_cortexa72_1 = "/cpus-a72@0/cpu@1";
                CPU_SLEEP_0 = "/cpus-a72@0/idle-states/cpu-sleep-0";
                cpus_microblaze_0 = "/cpus_microblaze@0";
                psv_pmc_0 = "/cpus_microblaze@0/cpu@0";
                cpus_microblaze_1 = "/cpus_microblaze@1";
                psv_psm_0 = "/cpus_microblaze@1/cpu@0";
                cpus_r5_0 = "/cpus-r5@0";
                psv_cortexr5_0 = "/cpus-r5@0/cpu@0";
                cpus_r5_1 = "/cpus-r5@1";
                psv_cortexr5_1 = "/cpus-r5@1/cpu@1";
                cpu_opp_table = "/opp-table-cpu";
                dcc = "/dcc";
                fpga = "/fpga-region";
                psci = "/psci";
                timer = "/timer";
                versal_fpga = "/versal-fpga";
                sensor0 = "/versal-thermal-sensor";
                versal_thermal = "/thermal-zones/versal-thermal";
                temp_alert = "/thermal-zones/versal-thermal/trips/temp-alert";
                ot_crit = "/thermal-zones/versal-thermal/trips/ot-crit";
                amba_apu = "/apu-bus";
                gic_a72 = "/apu-bus/interrupt-controller@f9000000";
                gic_its = "/apu-bus/interrupt-controller@f9000000/msi-controller@f9020000";
                amba_rpu = "/rpu-bus";
                gic_r5 = "/rpu-bus/interrupt-controller@f9000000";
                amba = "/axi";
                imux = "/axi/interrupt-multiplex";
                can0 = "/axi/can@ff060000";
                can1 = "/axi/can@ff070000";
                cci = "/axi/cci@fd000000";
                cci_pmu = "/axi/cci@fd000000/pmu@10000";
                lpd_dma_chan0 = "/axi/dma-controller@ffa80000";
                lpd_dma_chan1 = "/axi/dma-controller@ffa90000";
                lpd_dma_chan2 = "/axi/dma-controller@ffaa0000";
                lpd_dma_chan3 = "/axi/dma-controller@ffab0000";
                lpd_dma_chan4 = "/axi/dma-controller@ffac0000";
                lpd_dma_chan5 = "/axi/dma-controller@ffad0000";
                lpd_dma_chan6 = "/axi/dma-controller@ffae0000";
                lpd_dma_chan7 = "/axi/dma-controller@ffaf0000";
                gem0 = "/axi/ethernet@ff0c0000";
                mdio = "/axi/ethernet@ff0c0000/mdio";
                phy0 = "/axi/ethernet@ff0c0000/mdio/ethernet-phy@1";
                gem1 = "/axi/ethernet@ff0d0000";
                gpio0 = "/axi/gpio@ff0b0000";
                gpio1 = "/axi/gpio@f1020000";
                i2c0 = "/axi/i2c@ff020000";
                i2c1 = "/axi/i2c@ff030000";
                eeprom = "/axi/i2c@ff030000/eeprom@54";
                i2c2 = "/axi/i2c@f1000000";
                mc0 = "/axi/memory-controller@f6150000";
                mc1 = "/axi/memory-controller@f62c0000";
                mc2 = "/axi/memory-controller@f6430000";
                mc3 = "/axi/memory-controller@f65a0000";
                ocm = "/axi/memory-controller@ff960000";
                rtc = "/axi/rtc@f12a0000";
                sdhci0 = "/axi/mmc@f1040000";
                sdhci1 = "/axi/mmc@f1050000";
                serial0 = "/axi/serial@ff000000";
                serial1 = "/axi/serial@ff010000";
                smmu = "/axi/iommu@fd800000";
                ospi = "/axi/spi@f1010000";
                spi_flash = "/axi/spi@f1010000/flash@0";
                qspi = "/axi/spi@f1030000";
                spi0 = "/axi/spi@ff040000";
                spi1 = "/axi/spi@ff050000";
                sysmon0 = "/axi/sysmon@f1270000";
                sysmon1 = "/axi/sysmon@109270000";
                sysmon2 = "/axi/sysmon@111270000";
                sysmon3 = "/axi/sysmon@119270000";
                ttc0 = "/axi/timer@ff0e0000";
                ttc1 = "/axi/timer@ff0f0000";
                ttc2 = "/axi/timer@ff100000";
                ttc3 = "/axi/timer@ff110000";
                usb0 = "/axi/usb@ff9d0000";
                dwc3_0 = "/axi/usb@ff9d0000/usb@fe200000";
                cpm_pciea = "/axi/pci@fca10000";
                pcie_intc_0 = "/axi/pci@fca10000/interrupt-controller";
                cpm5_pcie = "/axi/pcie@fcdd0000";
                pcie_intc_2 = "/axi/pcie@fcdd0000/interrupt-controller";
                watchdog = "/axi/watchdog@fd4d0000";
                watchdog1 = "/axi/watchdog@ff120000";
                xilsem_edac = "/axi/edac@f2014050";
                dma0 = "/axi/pmcdma@f11c0000";
                dma1 = "/axi/pmcdma@f11d0000";
                pmc_trng = "/axi/pmc_trng@f1230000";
                pmc_cfi_cframe_0 = "/axi/cframe@f12d0000";
                pmc_cfu_apb_0 = "/axi/cfu_apb@f12b0000";
                pmc_ppu1_mdm_0 = "/axi/ppu1_mdm@f0310000";
                iomodule0 = "/axi/iomodule@f0280000";
                ipi_pmc = "/axi/mailbox@ff320000";
                ipi_pmc_to_ipi_0 = "/axi/mailbox@ff320000/child@0";
                ipi_pmc_to_ipi_1 = "/axi/mailbox@ff320000/child@1";
                ipi_pmc_to_ipi_2 = "/axi/mailbox@ff320000/child@2";
                ipi_pmc_to_ipi_3 = "/axi/mailbox@ff320000/child@3";
                ipi_pmc_to_ipi_4 = "/axi/mailbox@ff320000/child@4";
                ipi_pmc_to_ipi_5 = "/axi/mailbox@ff320000/child@5";
                ipi_pmc_to_ipi_6 = "/axi/mailbox@ff320000/child@6";
                ipi_pmc_to_ipi_pmc = "/axi/mailbox@ff320000/child@7";
                ipi_pmc_to_ipi_pmc_nobuf = "/axi/mailbox@ff320000/child@8";
                ipi_pmc_to_ipi_psm = "/axi/mailbox@ff320000/child@9";
                ipi_pmc_nobuf = "/axi/mailbox@ff390000";
                ipi_pmc_nobuf_to_ipi_0 = "/axi/mailbox@ff390000/child@0";
                ipi_pmc_nobuf_to_ipi_1 = "/axi/mailbox@ff390000/child@1";
                ipi_pmc_nobuf_to_ipi_2 = "/axi/mailbox@ff390000/child@2";
                ipi_pmc_nobuf_to_ipi_3 = "/axi/mailbox@ff390000/child@3";
                ipi_pmc_nobuf_to_ipi_4 = "/axi/mailbox@ff390000/child@4";
                ipi_pmc_nobuf_to_ipi_5 = "/axi/mailbox@ff390000/child@5";
                ipi_pmc_nobuf_to_ipi_6 = "/axi/mailbox@ff390000/child@6";
                ipi_pmc_nobuf_to_ipi_pmc = "/axi/mailbox@ff390000/child@7";
                ipi_pmc_nobuf_to_ipi_pmc_nobuf = "/axi/mailbox@ff390000/child@8";
                ipi_pmc_nobuf_to_ipi_psm = "/axi/mailbox@ff390000/child@9";
                ipi_psm = "/axi/mailbox@ff310000";
                ipi_psm_to_ipi_0 = "/axi/mailbox@ff310000/child@0";
                ipi_psm_to_ipi_1 = "/axi/mailbox@ff310000/child@1";
                ipi_psm_to_ipi_2 = "/axi/mailbox@ff310000/child@2";
                ipi_psm_to_ipi_3 = "/axi/mailbox@ff310000/child@3";
                ipi_psm_to_ipi_4 = "/axi/mailbox@ff310000/child@4";
                ipi_psm_to_ipi_5 = "/axi/mailbox@ff310000/child@5";
                ipi_psm_to_ipi_6 = "/axi/mailbox@ff310000/child@6";
                ipi_psm_to_ipi_pmc = "/axi/mailbox@ff310000/child@7";
                ipi_psm_to_ipi_pmc_nobuf = "/axi/mailbox@ff310000/child@8";
                ipi_psm_to_ipi_psm = "/axi/mailbox@ff310000/child@9";
                ipi0 = "/axi/mailbox@ff330000";
                ipi_0_to_ipi_0 = "/axi/mailbox@ff330000/child@0";
                ipi_0_to_ipi_1 = "/axi/mailbox@ff330000/child@1";
                ipi_0_to_ipi_2 = "/axi/mailbox@ff330000/child@2";
                ipi_0_to_ipi_3 = "/axi/mailbox@ff330000/child@3";
                ipi_0_to_ipi_4 = "/axi/mailbox@ff330000/child@4";
                ipi_0_to_ipi_5 = "/axi/mailbox@ff330000/child@5";
                ipi_0_to_ipi_6 = "/axi/mailbox@ff330000/child@6";
                ipi_0_to_ipi_pmc = "/axi/mailbox@ff330000/child@7";
                ipi_0_to_ipi_pmc_nobuf = "/axi/mailbox@ff330000/child@8";
                ipi_0_to_ipi_psm = "/axi/mailbox@ff330000/child@9";
                ipi1 = "/axi/mailbox@ff340000";
                ipi_1_to_ipi_0 = "/axi/mailbox@ff340000/child@0";
                ipi_1_to_ipi_1 = "/axi/mailbox@ff340000/child@1";
                ipi_1_to_ipi_2 = "/axi/mailbox@ff340000/child@2";
                ipi_1_to_ipi_3 = "/axi/mailbox@ff340000/child@3";
                ipi_1_to_ipi_4 = "/axi/mailbox@ff340000/child@4";
                ipi_1_to_ipi_5 = "/axi/mailbox@ff340000/child@5";
                ipi_1_to_ipi_6 = "/axi/mailbox@ff340000/child@6";
                ipi_1_to_ipi_pmc = "/axi/mailbox@ff340000/child@7";
                ipi_1_to_ipi_pmc_nobuf = "/axi/mailbox@ff340000/child@8";
                ipi_1_to_ipi_psm = "/axi/mailbox@ff340000/child@9";
                ipi2 = "/axi/mailbox@ff350000";
                ipi_2_to_ipi_0 = "/axi/mailbox@ff350000/child@0";
                ipi_2_to_ipi_1 = "/axi/mailbox@ff350000/child@1";
                ipi_2_to_ipi_2 = "/axi/mailbox@ff350000/child@2";
                ipi_2_to_ipi_3 = "/axi/mailbox@ff350000/child@3";
                ipi_2_to_ipi_4 = "/axi/mailbox@ff350000/child@4";
                ipi_2_to_ipi_5 = "/axi/mailbox@ff350000/child@5";
                ipi_2_to_ipi_6 = "/axi/mailbox@ff350000/child@6";
                ipi_2_to_ipi_pmc = "/axi/mailbox@ff350000/child@7";
                ipi_2_to_ipi_pmc_nobuf = "/axi/mailbox@ff350000/child@8";
                ipi_2_to_ipi_psm = "/axi/mailbox@ff350000/child@9";
                ipi3 = "/axi/mailbox@ff360000";
                ipi_3_to_ipi_0 = "/axi/mailbox@ff360000/child@0";
                ipi_3_to_ipi_1 = "/axi/mailbox@ff360000/child@1";
                ipi_3_to_ipi_2 = "/axi/mailbox@ff360000/child@2";
                ipi_3_to_ipi_3 = "/axi/mailbox@ff360000/child@3";
                ipi_3_to_ipi_4 = "/axi/mailbox@ff360000/child@4";
                ipi_3_to_ipi_5 = "/axi/mailbox@ff360000/child@5";
                ipi_3_to_ipi_6 = "/axi/mailbox@ff360000/child@6";
                ipi_3_to_ipi_pmc = "/axi/mailbox@ff360000/child@7";
                ipi_3_to_ipi_pmc_nobuf = "/axi/mailbox@ff360000/child@8";
                ipi_3_to_ipi_psm = "/axi/mailbox@ff360000/child@9";
                ipi4 = "/axi/mailbox@ff370000";
                ipi_4_to_ipi_0 = "/axi/mailbox@ff370000/child@0";
                ipi_4_to_ipi_1 = "/axi/mailbox@ff370000/child@1";
                ipi_4_to_ipi_2 = "/axi/mailbox@ff370000/child@2";
                ipi_4_to_ipi_3 = "/axi/mailbox@ff370000/child@3";
                ipi_4_to_ipi_4 = "/axi/mailbox@ff370000/child@4";
                ipi_4_to_ipi_5 = "/axi/mailbox@ff370000/child@5";
                ipi_4_to_ipi_6 = "/axi/mailbox@ff370000/child@6";
                ipi_4_to_ipi_pmc = "/axi/mailbox@ff370000/child@7";
                ipi_4_to_ipi_pmc_nobuf = "/axi/mailbox@ff370000/child@8";
                ipi_4_to_ipi_psm = "/axi/mailbox@ff370000/child@9";
                ipi5 = "/axi/mailbox@ff380000";
                ipi_5_to_ipi_0 = "/axi/mailbox@ff380000/child@0";
                ipi_5_to_ipi_1 = "/axi/mailbox@ff380000/child@1";
                ipi_5_to_ipi_2 = "/axi/mailbox@ff380000/child@2";
                ipi_5_to_ipi_3 = "/axi/mailbox@ff380000/child@3";
                ipi_5_to_ipi_4 = "/axi/mailbox@ff380000/child@4";
                ipi_5_to_ipi_5 = "/axi/mailbox@ff380000/child@5";
                ipi_5_to_ipi_6 = "/axi/mailbox@ff380000/child@6";
                ipi_5_to_ipi_pmc = "/axi/mailbox@ff380000/child@7";
                ipi_5_to_ipi_pmc_nobuf = "/axi/mailbox@ff380000/child@8";
                ipi_5_to_ipi_psm = "/axi/mailbox@ff380000/child@9";
                ipi6 = "/axi/mailbox@ff3a0000";
                ipi_6_to_ipi_0 = "/axi/mailbox@ff3a0000/child@0";
                ipi_6_to_ipi_1 = "/axi/mailbox@ff3a0000/child@1";
                ipi_6_to_ipi_2 = "/axi/mailbox@ff3a0000/child@2";
                ipi_6_to_ipi_3 = "/axi/mailbox@ff3a0000/child@3";
                ipi_6_to_ipi_4 = "/axi/mailbox@ff3a0000/child@4";
                ipi_6_to_ipi_5 = "/axi/mailbox@ff3a0000/child@5";
                ipi_6_to_ipi_6 = "/axi/mailbox@ff3a0000/child@6";
                ipi_6_to_ipi_pmc = "/axi/mailbox@ff3a0000/child@7";
                ipi_6_to_ipi_pmc_nobuf = "/axi/mailbox@ff3a0000/child@8";
                ipi_6_to_ipi_psm = "/axi/mailbox@ff3a0000/child@9";
                coresight = "/axi/coresight@f0800000";
                CIPS_0_pspmc_0_psv_apu_0 = "/axi/CIPS_0_pspmc_0_psv_apu_0@fd5c0000";
                CIPS_0_pspmc_0_psv_coresight_a720_cti = "/axi/CIPS_0_pspmc_0_psv_coresight_a720_cti@f0d10000";
                CIPS_0_pspmc_0_psv_coresight_a720_dbg = "/axi/CIPS_0_pspmc_0_psv_coresight_a720_dbg@f0d00000";
                CIPS_0_pspmc_0_psv_coresight_a720_etm = "/axi/CIPS_0_pspmc_0_psv_coresight_a720_etm@f0d30000";
                CIPS_0_pspmc_0_psv_coresight_a720_pmu = "/axi/CIPS_0_pspmc_0_psv_coresight_a720_pmu@f0d20000";
                CIPS_0_pspmc_0_psv_coresight_a721_cti = "/axi/CIPS_0_pspmc_0_psv_coresight_a721_cti@f0d50000";
                CIPS_0_pspmc_0_psv_coresight_a721_dbg = "/axi/CIPS_0_pspmc_0_psv_coresight_a721_dbg@f0d40000";
                CIPS_0_pspmc_0_psv_coresight_a721_etm = "/axi/CIPS_0_pspmc_0_psv_coresight_a721_etm@f0d70000";
                CIPS_0_pspmc_0_psv_coresight_a721_pmu = "/axi/CIPS_0_pspmc_0_psv_coresight_a721_pmu@f0d60000";
                CIPS_0_pspmc_0_psv_coresight_apu_cti = "/axi/CIPS_0_pspmc_0_psv_coresight_apu_cti@f0ca0000";
                CIPS_0_pspmc_0_psv_coresight_apu_ela = "/axi/CIPS_0_pspmc_0_psv_coresight_apu_ela@f0c60000";
                CIPS_0_pspmc_0_psv_coresight_apu_etf = "/axi/CIPS_0_pspmc_0_psv_coresight_apu_etf@f0c30000";
                CIPS_0_pspmc_0_psv_coresight_apu_fun = "/axi/CIPS_0_pspmc_0_psv_coresight_apu_fun@f0c20000";
                CIPS_0_pspmc_0_psv_coresight_cpm_atm = "/axi/CIPS_0_pspmc_0_psv_coresight_cpm_atm@f0f80000";
                CIPS_0_pspmc_0_psv_coresight_cpm_cti2a = "/axi/CIPS_0_pspmc_0_psv_coresight_cpm_cti2a@f0fa0000";
                CIPS_0_pspmc_0_psv_coresight_cpm_cti2d = "/axi/CIPS_0_pspmc_0_psv_coresight_cpm_cti2d@f0fd0000";
                CIPS_0_pspmc_0_psv_coresight_cpm_ela2a = "/axi/CIPS_0_pspmc_0_psv_coresight_cpm_ela2a@f0f40000";
                CIPS_0_pspmc_0_psv_coresight_cpm_ela2b = "/axi/CIPS_0_pspmc_0_psv_coresight_cpm_ela2b@f0f50000";
                CIPS_0_pspmc_0_psv_coresight_cpm_ela2c = "/axi/CIPS_0_pspmc_0_psv_coresight_cpm_ela2c@f0f60000";
                CIPS_0_pspmc_0_psv_coresight_cpm_ela2d = "/axi/CIPS_0_pspmc_0_psv_coresight_cpm_ela2d@f0f70000";
                CIPS_0_pspmc_0_psv_coresight_cpm_fun = "/axi/CIPS_0_pspmc_0_psv_coresight_cpm_fun@f0f20000";
                CIPS_0_pspmc_0_psv_coresight_cpm_rom = "/axi/CIPS_0_pspmc_0_psv_coresight_cpm_rom@f0f00000";
                CIPS_0_pspmc_0_psv_coresight_fpd_atm = "/axi/CIPS_0_pspmc_0_psv_coresight_fpd_atm@f0b80000";
                CIPS_0_pspmc_0_psv_coresight_fpd_cti1b = "/axi/CIPS_0_pspmc_0_psv_coresight_fpd_cti1b@f0bb0000";
                CIPS_0_pspmc_0_psv_coresight_fpd_cti1c = "/axi/CIPS_0_pspmc_0_psv_coresight_fpd_cti1c@f0bc0000";
                CIPS_0_pspmc_0_psv_coresight_fpd_cti1d = "/axi/CIPS_0_pspmc_0_psv_coresight_fpd_cti1d@f0bd0000";
                CIPS_0_pspmc_0_psv_coresight_fpd_stm = "/axi/CIPS_0_pspmc_0_psv_coresight_fpd_stm@f0b70000";
                CIPS_0_pspmc_0_psv_coresight_lpd_atm = "/axi/CIPS_0_pspmc_0_psv_coresight_lpd_atm@f0980000";
                CIPS_0_pspmc_0_psv_coresight_lpd_cti = "/axi/CIPS_0_pspmc_0_psv_coresight_lpd_cti@f09d0000";
                CIPS_0_pspmc_0_psv_coresight_pmc_cti = "/axi/CIPS_0_pspmc_0_psv_coresight_pmc_cti@f08d0000";
                CIPS_0_pspmc_0_psv_coresight_r50_cti = "/axi/CIPS_0_pspmc_0_psv_coresight_r50_cti@f0a10000";
                CIPS_0_pspmc_0_psv_coresight_r51_cti = "/axi/CIPS_0_pspmc_0_psv_coresight_r51_cti@f0a50000";
                CIPS_0_pspmc_0_psv_cpm = "/axi/CIPS_0_pspmc_0_psv_cpm@0";
                CIPS_0_pspmc_0_psv_crf_0 = "/axi/CIPS_0_pspmc_0_psv_crf_0@fd1a0000";
                CIPS_0_pspmc_0_psv_crl_0 = "/axi/CIPS_0_pspmc_0_psv_crl_0@ff5e0000";
                CIPS_0_pspmc_0_psv_crp_0 = "/axi/CIPS_0_pspmc_0_psv_crp_0@f1260000";
                CIPS_0_pspmc_0_psv_fpd_afi_0 = "/axi/CIPS_0_pspmc_0_psv_fpd_afi_0@fd360000";
                CIPS_0_pspmc_0_psv_fpd_afi_2 = "/axi/CIPS_0_pspmc_0_psv_fpd_afi_2@fd380000";
                CIPS_0_pspmc_0_psv_fpd_afi_mem_0 = "/axi/CIPS_0_pspmc_0_psv_fpd_afi_mem_0@a4000000";
                CIPS_0_pspmc_0_psv_fpd_afi_mem_2 = "/axi/CIPS_0_pspmc_0_psv_fpd_afi_mem_2@b0000000";
                CIPS_0_pspmc_0_psv_fpd_cci_0 = "/axi/CIPS_0_pspmc_0_psv_fpd_cci_0@fd5e0000";
                CIPS_0_pspmc_0_psv_fpd_gpv_0 = "/axi/CIPS_0_pspmc_0_psv_fpd_gpv_0@fd700000";
                CIPS_0_pspmc_0_psv_fpd_slcr_0 = "/axi/CIPS_0_pspmc_0_psv_fpd_slcr_0@fd610000";
                CIPS_0_pspmc_0_psv_fpd_slcr_secure_0 = "/axi/CIPS_0_pspmc_0_psv_fpd_slcr_secure_0@fd690000";
                CIPS_0_pspmc_0_psv_fpd_smmu_0 = "/axi/CIPS_0_pspmc_0_psv_fpd_smmu_0@fd5f0000";
                CIPS_0_pspmc_0_psv_ipi_buffer = "/axi/CIPS_0_pspmc_0_psv_ipi_buffer@ff3f0000";
                CIPS_0_pspmc_0_psv_lpd_afi_0 = "/axi/CIPS_0_pspmc_0_psv_lpd_afi_0@ff9b0000";
                CIPS_0_pspmc_0_psv_lpd_afi_mem_0 = "/axi/CIPS_0_pspmc_0_psv_lpd_afi_mem_0@80000000";
                CIPS_0_pspmc_0_psv_lpd_iou_secure_slcr_0 = "/axi/CIPS_0_pspmc_0_psv_lpd_iou_secure_slcr_0@ff0a0000";
                CIPS_0_pspmc_0_psv_lpd_iou_slcr_0 = "/axi/CIPS_0_pspmc_0_psv_lpd_iou_slcr_0@ff080000";
                CIPS_0_pspmc_0_psv_lpd_slcr_0 = "/axi/CIPS_0_pspmc_0_psv_lpd_slcr_0@ff410000";
                CIPS_0_pspmc_0_psv_lpd_slcr_secure_0 = "/axi/CIPS_0_pspmc_0_psv_lpd_slcr_secure_0@ff510000";
                CIPS_0_pspmc_0_psv_ocm_ctrl = "/axi/CIPS_0_pspmc_0_psv_ocm_ctrl@ff960000";
                CIPS_0_pspmc_0_psv_pmc_aes = "/axi/CIPS_0_pspmc_0_psv_pmc_aes@f11e0000";
                CIPS_0_pspmc_0_psv_pmc_analog_0 = "/axi/CIPS_0_pspmc_0_psv_pmc_analog_0@f1160000";
                CIPS_0_pspmc_0_psv_pmc_bbram_ctrl = "/axi/CIPS_0_pspmc_0_psv_pmc_bbram_ctrl@f11f0000";
                CIPS_0_pspmc_0_psv_pmc_efuse_cache = "/axi/CIPS_0_pspmc_0_psv_pmc_efuse_cache@f1250000";
                CIPS_0_pspmc_0_psv_pmc_efuse_ctrl = "/axi/CIPS_0_pspmc_0_psv_pmc_efuse_ctrl@f1240000";
                CIPS_0_pspmc_0_psv_pmc_global_0 = "/axi/CIPS_0_pspmc_0_psv_pmc_global_0@f1110000";
                CIPS_0_pspmc_0_psv_pmc_ram = "/axi/CIPS_0_pspmc_0_psv_pmc_ram@f2000000";
                CIPS_0_pspmc_0_psv_pmc_ram_data_cntlr = "/axi/CIPS_0_pspmc_0_psv_pmc_ram_data_cntlr@f0240000";
                CIPS_0_pspmc_0_psv_pmc_ram_instr_cntlr = "/axi/CIPS_0_pspmc_0_psv_pmc_ram_instr_cntlr@f0200000";
                CIPS_0_pspmc_0_psv_pmc_ram_npi = "/axi/CIPS_0_pspmc_0_psv_pmc_ram_npi@f6000000";
                CIPS_0_pspmc_0_psv_pmc_rsa = "/axi/CIPS_0_pspmc_0_psv_pmc_rsa@f1200000";
                CIPS_0_pspmc_0_psv_pmc_sha = "/axi/CIPS_0_pspmc_0_psv_pmc_sha@f1210000";
                CIPS_0_pspmc_0_psv_pmc_slave_boot = "/axi/CIPS_0_pspmc_0_psv_pmc_slave_boot@f1220000";
                CIPS_0_pspmc_0_psv_pmc_slave_boot_stream = "/axi/CIPS_0_pspmc_0_psv_pmc_slave_boot_stream@f2100000";
                CIPS_0_pspmc_0_psv_pmc_tap = "/axi/CIPS_0_pspmc_0_psv_pmc_tap@f11a0000";
                CIPS_0_pspmc_0_psv_pmc_tmr_inject_0 = "/axi/CIPS_0_pspmc_0_psv_pmc_tmr_inject_0@f0083000";
                CIPS_0_pspmc_0_psv_pmc_tmr_manager_0 = "/axi/CIPS_0_pspmc_0_psv_pmc_tmr_manager_0@f0283000";
                CIPS_0_pspmc_0_psv_psm_global_reg = "/axi/CIPS_0_pspmc_0_psv_psm_global_reg@ffc90000";
                CIPS_0_pspmc_0_psv_psm_iomodule_0 = "/axi/CIPS_0_pspmc_0_psv_psm_iomodule_0@ffc80000";
                CIPS_0_pspmc_0_psv_psm_ram_data_cntlr = "/axi/CIPS_0_pspmc_0_psv_psm_ram_data_cntlr@ffc20000";
                CIPS_0_pspmc_0_psv_psm_ram_instr_cntlr = "/axi/CIPS_0_pspmc_0_psv_psm_ram_instr_cntlr@ffc00000";
                CIPS_0_pspmc_0_psv_psm_tmr_inject_0 = "/axi/CIPS_0_pspmc_0_psv_psm_tmr_inject_0@ffcd0000";
                CIPS_0_pspmc_0_psv_psm_tmr_manager_0 = "/axi/CIPS_0_pspmc_0_psv_psm_tmr_manager_0@ffcc0000";
                CIPS_0_pspmc_0_psv_r5_0_atcm = "/axi/CIPS_0_pspmc_0_psv_r5_0_atcm@0";
                CIPS_0_pspmc_0_psv_r5_0_atcm_lockstep = "/axi/CIPS_0_pspmc_0_psv_r5_0_atcm_lockstep@ffe10000";
                CIPS_0_pspmc_0_psv_r5_0_btcm = "/axi/CIPS_0_pspmc_0_psv_r5_0_btcm@20000";
                CIPS_0_pspmc_0_psv_r5_0_btcm_lockstep = "/axi/CIPS_0_pspmc_0_psv_r5_0_btcm_lockstep@ffe30000";
                CIPS_0_pspmc_0_psv_r5_0_data_cache = "/axi/CIPS_0_pspmc_0_psv_r5_0_data_cache@ffe50000";
                CIPS_0_pspmc_0_psv_r5_0_instruction_cache = "/axi/CIPS_0_pspmc_0_psv_r5_0_instruction_cache@ffe40000";
                CIPS_0_pspmc_0_psv_r5_1_atcm = "/axi/CIPS_0_pspmc_0_psv_r5_1_atcm@0";
                CIPS_0_pspmc_0_psv_r5_1_btcm = "/axi/CIPS_0_pspmc_0_psv_r5_1_btcm@20000";
                CIPS_0_pspmc_0_psv_r5_1_data_cache = "/axi/CIPS_0_pspmc_0_psv_r5_1_data_cache@ffed0000";
                CIPS_0_pspmc_0_psv_r5_1_instruction_cache = "/axi/CIPS_0_pspmc_0_psv_r5_1_instruction_cache@ffec0000";
                CIPS_0_pspmc_0_psv_r5_tcm_ram_0 = "/axi/CIPS_0_pspmc_0_psv_r5_tcm_ram_0@0";
                CIPS_0_pspmc_0_psv_rpu_0 = "/axi/CIPS_0_pspmc_0_psv_rpu_0@ff9a0000";
                CIPS_0_pspmc_0_psv_scntr_0 = "/axi/CIPS_0_pspmc_0_psv_scntr_0@ff130000";
                CIPS_0_pspmc_0_psv_scntrs_0 = "/axi/CIPS_0_pspmc_0_psv_scntrs_0@ff140000";
                psv_r5_0_atcm_global = "/psv_r5_0_atcm_global@ffe00000";
                psv_r5_0_btcm_global = "/psv_r5_0_btcm_global@ffe20000";
                psv_r5_1_atcm_global = "/psv_r5_1_atcm_global@ffe90000";
                psv_r5_1_btcm_global = "/psv_r5_1_btcm_global@ffeb0000";
                amba_xppu = "/indirect-bus@1";
                lpd_xppu = "/indirect-bus@1/xppu@ff990000";
                pmc_xppu = "/indirect-bus@1/xppu@f1310000";
                pmc_xppu_npi = "/indirect-bus@1/xppu@f1300000";
                amba_xmpu = "/indirect-bus@2";
                fpd_xmpu = "/indirect-bus@2/xmpu@fd390000";
                pmc_xmpu = "/indirect-bus@2/xmpu@f12f0000";
                ocm_xmpu = "/indirect-bus@2/xmpu@ff980000";
                ddrmc_xmpu_0 = "/indirect-bus@2/xmpu@f6080000";
                ddrmc_xmpu_1 = "/indirect-bus@2/xmpu@f6220000";
                ddrmc_xmpu_2 = "/indirect-bus@2/xmpu@f6390000";
                ddrmc_xmpu_3 = "/indirect-bus@2/xmpu@f6500000";
                pl_alt_ref = "/pl-alt-ref";
                ref = "/ref";
                can0_clk = "/can0-clk";
                can1_clk = "/can1-clk";
                versal_firmware = "/firmware/versal-firmware";
                versal_clk = "/firmware/versal-firmware/clock-controller";
                zynqmp_power = "/firmware/versal-firmware/power-management";
                versal_reset = "/firmware/versal-firmware/reset-controller";
                pinctrl0 = "/firmware/versal-firmware/pinctrl";
                versal_sec_cfg = "/firmware/versal-firmware/versal-sec-cfg";
                bbram_zeroize = "/firmware/versal-firmware/versal-sec-cfg/nvmem-layout/bbram-zeroize@4";
                bbram_key = "/firmware/versal-firmware/versal-sec-cfg/nvmem-layout/bbram-key@10";
                bbram_usr = "/firmware/versal-firmware/versal-sec-cfg/nvmem-layout/bbram-usr@30";
                bbram_lock = "/firmware/versal-firmware/versal-sec-cfg/nvmem-layout/bbram-lock@48";
                user_key0 = "/firmware/versal-firmware/versal-sec-cfg/nvmem-layout/user-key@110";
                user_key1 = "/firmware/versal-firmware/versal-sec-cfg/nvmem-layout/user-key@130";
                user_key2 = "/firmware/versal-firmware/versal-sec-cfg/nvmem-layout/user-key@150";
                user_key3 = "/firmware/versal-firmware/versal-sec-cfg/nvmem-layout/user-key@170";
                user_key4 = "/firmware/versal-firmware/versal-sec-cfg/nvmem-layout/user-key@190";
                user_key5 = "/firmware/versal-firmware/versal-sec-cfg/nvmem-layout/user-key@1b0";
                user_key6 = "/firmware/versal-firmware/versal-sec-cfg/nvmem-layout/user-key@1d0";
                user_key7 = "/firmware/versal-firmware/versal-sec-cfg/nvmem-layout/user-key@1f0";
                amba_pl = "/amba_pl";
                misc_clk_0 = "/amba_pl/misc_clk_0";
                ai_engine_0 = "/amba_pl/ai_engine@20000000000";
                aie_aperture_0 = "/amba_pl/ai_engine@20000000000/aie_aperture@20000000000";
                axi_bram_ctrl_0 = "/amba_pl/axi_bram_ctrl_0@a4010000";
                axi_gpio_0 = "/amba_pl/gpio@a6010000";
                axi_gpio_1 = "/amba_pl/gpio@a6020000";
                axi_gpio_2 = "/amba_pl/gpio@a4000000";
                aie_core_ref_clk_0 = "/amba_pl/aie_core_ref_clk_0";
                noc_lpddr0_ddr_memory = "/memory@00000000";
                noc_lpddr1_ddr_memory = "/memory@50000000000";
                noc_lpddr2_ddr_memory = "/memory@60000000000";
                axi_bram_ctrl_0_memory = "/memory@a4010000";
                CIPS_0_pspmc_0_psv_ocm_ram_0_memory = "/memory@FFFC0000";
        };

        reserved-memory {
                ranges = <0x1>;

                rpu0vdev0vring1 {
                        phandle = <0x162>;
                        no-map = <0x1>;
                        size = <0x4000>;
                        start = <0x9864000>;
                };

                rpu0vdev0vring0 {
                        phandle = <0x163>;
                        no-map = <0x1>;
                        size = <0x4000>;
                        start = <0x9860000>;
                };

                rpu0vdev0buffer {
                        phandle = <0x164>;
                        no-map = <0x1>;
                        size = <0x100000>;
                        start = <0x9868000>;
                };

                rproc0 {
                        no-map = <0x1>;
                        size = <0x60000>;
                        start = <0x9800000>;
                };
        };

        domains {

                openamp_a72_0_cluster {
                        compatible = "openamp,domain-v1";
                        os,type = "linux";
                        access = <&cpus_r5_0 0x0>,
                         <&ipi1 0x0>,
                         <&ipi3 0x0>,
                         <&psv_r5_0_atcm_global 0x0>,
                         <&psv_r5_0_btcm_global 0x0>;
                        access-json = "[{\"dev\": \"cpus_r5_0\", \"flags\": 0}, {\"dev\": \"ipi1\", \"flags\": 0}, {\"dev\": \"ipi3\", \"flags\": 0}, {\"dev\": \"psv_r5_0_atcm_global@ffe00000\", \"flags\": {}}, {\"dev\": \"psv_r5_0_btcm_global@ffe20000\", \"flags\": 0}, {\"dev\": \"amba_pl\"}, {\"dev\": \"ethernet@ff0d0000\"}, {\"dev\": \"spi@f1030000\"}, {\"dev\": \"mmc@f1040000\"}]";
                        phandle = <0x15e>;

                        reserved-memory {
                                ranges = <0x1>;
                                #size-cells = <0x2>;
                                #address-cells = <0x2>;

                                rpu0vdev0vring1 {
                                        start = <0x9864000>;
                                        size = <0x4000>;
                                        no-map = <0x1>;
                                        phandle = <0x15c>;
                                };

                                rpu0vdev0vring0 {
                                        start = <0x9860000>;
                                        size = <0x4000>;
                                        no-map = <0x1>;
                                        phandle = <0x15b>;
                                };

                                rpu0vdev0buffer {
                                        start = <0x9868000>;
                                        size = <0x100000>;
                                        no-map = <0x1>;
                                        phandle = <0x15d>;
                                };

                                rproc0 {
                                        start = <0x9800000>;
                                        size = <0x60000>;
                                        no-map = <0x1>;
                                        phandle = <0x15a>;
                                };
                        };

                        domain-to-domain {
                                compatible = "openamp,domain-to-domain-v1";

                                remoteproc-relation {
                                        compatible = "openamp,remoteproc-v2";
                                        remote = <0x159>;
                                        elfload;
                                        elfload0 = <0x79 0x141 0x15a>;
                                };

                                rpmsg-relation {
                                        compatible = "openamp,rpmsg-v1";
                                        openamp-xlnx-native = <0x0 0x0>;
                                        remote = <0x159>;
                                        mbox = <0xa>;
                                        carveouts = <0x15b 0x15c 0x15d>;
                                };
                        };
                };

                openamp_r5_0_cluster {
                        compatible = "openamp,domain-v1";
                        cpus = <&cpus_r5_0 0x1 0x0>;
                        os,type = "freertos";
                        access = <&psv_r5_0_atcm_global 0x0>,
                         <&psv_r5_0_btcm_global 0x0>,
                         <&ipi1 0x0>,
                         <&ipi3 0x0>,
                         <&noc_lpddr0_ddr_memory 0x0>,
                         <&noc_lpddr0_ddr_memory 0x0>,
                         <&ttc0 0x0>,
                         <&CIPS_0_pspmc_0_psv_rpu_0 0x0>;
                        cpu_config_str = "split";
                        core_num = "0";
                        phandle = <0x159>;
                        access-json = "[{\"dev\": \"psv_r5_0_atcm_global@ffe00000\", \"flags\": 0}, {\"dev\": \"psv_r5_0_btcm_global@ffe20000\", \"flags\": 0}, {\"dev\": \"ipi1\", \"flags\": 0}, {\"dev\": \"ipi3\", \"flags\": 0}, {\"dev\": \"noc_lpddr0_ddr_memory\", \"flags\": 0}, {\"dev\": \"memory@00000000\", \"flags\": 0}, {\"dev\": \"timer@ff0e0000\", \"flags\": 0}, {\"dev\": \"ps_wizard_0_pmcps_0_psv_rpu_0@ff9a0000\", \"flags\": 0}, {\"dev\": \"CIPS_0_pspmc_0_psv_rpu_0@ff9a0000\", \"flags\": 0}]";

                        reserved-memory {
                                ranges = <0x1>;

                                rpu0vdev0vring1 {
                                        start = <0x9864000>;
                                        size = <0x4000>;
                                        no-map = <0x1>;
                                        phandle = <0x160>;
                                };

                                rpu0vdev0vring0 {
                                        start = <0x9860000>;
                                        size = <0x4000>;
                                        no-map = <0x1>;
                                        phandle = <0x15f>;
                                };

                                rpu0vdev0buffer {
                                        start = <0x9868000>;
                                        size = <0x100000>;
                                        no-map = <0x1>;
                                        phandle = <0x161>;
                                };

                                rproc0 {
                                        start = <0x9800000>;
                                        size = <0x60000>;
                                        no-map = <0x1>;
                                };
                        };

                        domain-to-domain {
                                compatible = "openamp,domain-to-domain-v1";
                                cluster_cpu = "psv_cortexr5_0";

                                rpmsg-relation {
                                        compatible = "openamp,rpmsg-v1";
                                        host = <0x15e>;
                                        mbox = <0x8b>;
                                        carveouts = <0x15f 0x160 0x161>;
                                };
                        };
                };
        };
};
